# EOS-S3 register map
File version: 0.1
CPU: CM4 r0p1, selectable endian, MPU, FPU, 3 interrupt priority bits
Registers are 32-bit, read-write, reset 0x0 unless marked. A register's access mark holds for its fields unless they carry their own. Offsets are from the block's base; [hi:lo] are bit positions; {n}, {i} and the like mark numbered series; 'fields as' and 'values as' point back to an identical list.

## UART — Universal Asynchronous Receiver Transmitter
Base 0x40010000
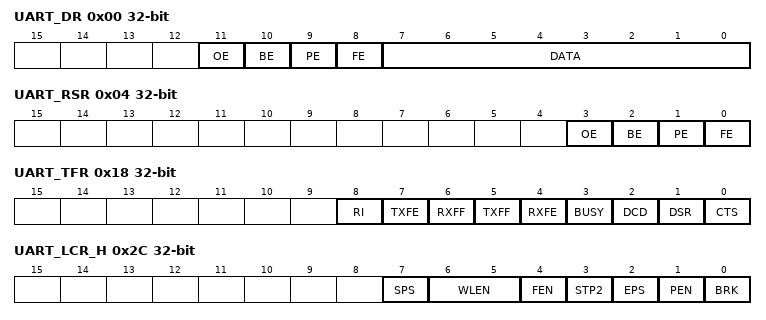
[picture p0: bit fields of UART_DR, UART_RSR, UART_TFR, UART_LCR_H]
0x00 UART_DR — Uart Data register
  [11] OE — Overrun error. This bit is set to 1 if data is received and the receive FIFO is already full. This is cleared to 0 once there is an empty space in the FIFO and a new character can be written to it.
  [10] BE — Break error. This bit is set to 1 if a break condition was detected, indicating that the received data input was held LOW for longer than a full-word transmission time (defined as start, data, parity and stop bits). In FIFO mode, this error is associated with the character at the top of the FIFO. When a break occurs, only one 0 character is loaded into the FIFO. The next character is only enabled after the receive data input goes to a 1 (marking state), and the next valid start bit is received.
  [9] PE — Parity error. When set to 1, it indicates that the parity of the received data character does not match the parity that the EPS and SPS bits in the Line Control Register, UARTLCR_H on page 3-12 select. In FIFO mode, this error is associated with the character at the top of the FIFO.
  [8] FE — Framing error. When set to 1, it indicates that the received character did not have a valid stop bit (a valid stop bit is 1). In FIFO mode, this error is associated with the character at the top of the FIFO.
  [7:0] DATA — Receive (read) data character. Transmit (write) data character.
0x00 UART_IBRD — The integer baud rate divisor.
  [15:0] UART_IBRD
0x00 UART_FBRD — The fractional baud rate divisor.
  [5:0] UART_FBRD
0x04 UART_RSR — UART receive status register/error clear register. (WC)
  [3] OE — Overrun error. This bit is set to 1 if data is received and the FIFO is already full. This bit is cleared to 0 by a write to UARTECR. The FIFO contents remain valid because no more data is written when the FIFO is full, only the contents of the shift register are overwritten. The CPU must now read the data, to empty the FIFO.
  [2] BE — Break error. This bit is set to 1 if a break condition was detected, indicating that the received data input was held LOW for longer than a full-word transmission time (defined as start, data, parity, and stop bits). This bit is cleared to 0 after a write to UARTECR. In FIFO mode, this error is associated with the character at the top of the FIFO. When a break occurs, only one 0 character is loaded into the FIFO. The next character is only enabled after the receive data input goes to a 1 (marking state) and the next valid start bit is received.
  [1] PE — Parity error. When set to 1, it indicates that the parity of the received data character does not match the parity that the EPS and SPS bits in the Line Control Register, UARTLCR_H on page 3-12 select. This bit is cleared to 0 by a write to UARTECR. In FIFO mode, this error is associated with the character at the top of the FIFO.
  [0] FE — Framing error. When set to 1, it indicates that the received character did not have a valid stop bit (a valid stop bit is 1). This bit is cleared to 0 by a write to UARTECR. In FIFO mode, this error is associated with the character at the top of the FIFO
0x18 UART_TFR — UART Flag Register
  [8] RI ro — Ring indicator. This bit is the complement of the UART ring indicator, nUARTRI, modem status input. That is, the bit is 1 when nUARTRI is LOW.
  [7] TXFE ro — Transmit FIFO empty. The meaning of this bit depends on the state of the FEN bit in the Line Control Register, UARTLCR_H on page 3-12. If the FIFO is disabled, this bit is set when the transmit holding register is empty. If the FIFO is enabled, the TXFE bit is set when the transmit FIFO is empty. This bit does not indicate if there is data in the transmit shift register.
  [6] RXFF ro — Receive FIFO full. The meaning of this bit depends on the state of the FEN bit in the UARTLCR_H Register. If the FIFO is disabled, this bit is set when the receive holding register is full. If the FIFO is enabled, the RXFF bit is set when the receive FIFO is full.
  [5] TXFF ro — Transmit FIFO full. The meaning of this bit depends on the state of the FEN bit in the UARTLCR_H Register. If the FIFO is disabled, this bit is set when the transmit holding register is full. If the FIFO is enabled, the TXFF bit is set when the transmit FIFO is full.
  [4] RXFE ro — Receive FIFO empty. The meaning of this bit depends on the state of the FEN bit in the UARTLCR_H Register. If the FIFO is disabled, this bit is set when the receive holding register is empty. If the FIFO is enabled, the RXFE bit is set when the receive FIFO is empty.
  [3] BUSY ro — UART busy. If this bit is set to 1, the UART is busy transmitting data. This bit remains set until the complete byte, including all the stop bits, has been sent from the shift register. This bit is set as soon as the transmit FIFO becomes non-empty, regardless of whether the UART is enabled or not.
  [2] DCD ro — Data carrier detect. This bit is the complement of the UART data carrier detect, nUARTDCD, modem status input. That is, the bit is 1 when nUARTDCD is LOW.
  [1] DSR ro — Data set ready. This bit is the complement of the UART data set ready, nUARTDSR, modem status input. That is, the bit is 1 when nUARTDSR is LOW.
  [0] CTS ro — Clear to send. This bit is the complement of the UART clear to send, nUARTCTS, modem status input. That is, the bit is 1 when nUARTCTS is LOW.
0x20 UART_ILPR — 8-bit low-power divisor value.
  [7:0] UART_ILPR
0x2C UART_LCR_H — UART Line Control Register. This register accesses bit 29 to 22 of the UART Line Control Register, UARTLCR.
  [7] SPS — Stick parity select. This bit has no effect when the PEN bit disables parity checking and generation. See Table 3-11 on page 3-14 for the parity truth table.
    0=disable_stick_parity (Stick parity is disabled); 1=enable_stick_parity (If EPS = 1 => parity bit is trasmitted and checked as a 1, If EPS = 0 => parity bit is trasmitted an checked as a 0)
  [6:5] WLEN — Word length. These bits indicate the number of data bits transmitted or received in a frame
    {v}=use_{v+5}_bit_word (Word lenght of data bits is will be configured as {v+5} bit) (v=0..3)
  [4] FEN — Enable FIFOs:
    0=disable_fifos (FIFOs are disabled (character mode) that is, the FIFOs become 1-byte-deep holding registers); 1=enable_fifos (transmit and receive FIFO buffers are enabled (FIFO mode).)
  [3] STP2 — Two stop bits select. If this bit is set to 1, two stop bits are transmitted at the end of the frame. The receive logic does not check for two stop bits being received.
  [2] EPS — Even parity select. Controls the type of parity the UART uses during transmission and reception. This bit has no effect when the PEN bit disables parity checking and generation. See Table 3-11 on page 3-14 for the parity truth table.
    0=odd_parity (Select odd parity. The UART generates or checks for an odd number of 1s in the data and parity bits.); 1=even_parity (Select even parity. The UART generates or checks for an even number of 1s in the data and parity bits.)
  [1] PEN — Parity enable. See Table 3-11 on page 3-14 for the parity truth table.
    0=parity_disable (parity is disabled and no parity bit added to the data frame); 1=parity_enable (parity checking and generation is enabled.)
  [0] BRK — Send break. If this bit is set to 1, a low-level is continually output on the UARTTXD output, after completing transmission of the current character. For the proper execution of the break command, the software must set this bit for at least two complete frames. For normal use, this bit must be cleared to 0.
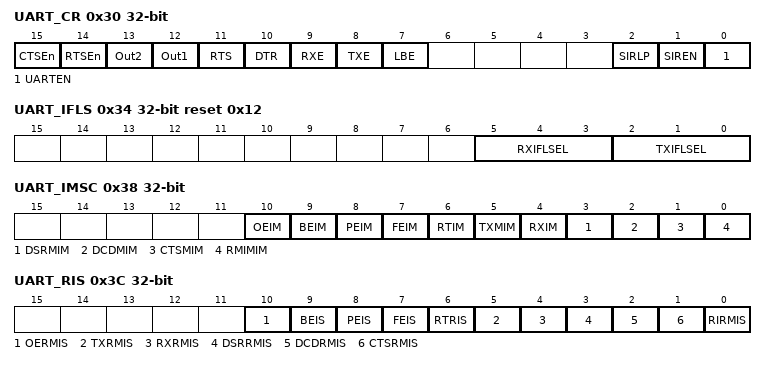
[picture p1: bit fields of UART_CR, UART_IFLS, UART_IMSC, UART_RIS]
0x30 UART_CR — UART Control Register
  [15] CTSEn — CTS hardware flow control enable. If this bit is set to 1, CTS hardware flow control is enabled. Data is only transmitted when the nUARTCTS signal is asserted.
  [14] RTSEn — RTS hardware flow control enable. If this bit is set to 1, RTS hardware flow control is enabled. Data is only requested when there is space in the receive FIFO for it to be received.
  [13] Out2 — This bit is the complement of the UART Out2 (nUARTOut2) modem status output. That is, when the bit is programmed to a 1, the output is 0. For DTE this can be used as Ring Indicator (RI).
  [12] Out1 — This bit is the complement of the UART Out1 (nUARTOut1) modem status output. That is, when the bit is programmed to a 1 the output is 0. For DTE this can be used as Data Carrier Detect (DCD).
  [11] RTS — Request to send. This bit is the complement of the UART request to send, nUARTRTS, modem status output. That is, when the bit is programmed to a 1 then nUARTRTS is LOW.
  [10] DTR — Receive enable. If this bit is set to 1, the receive section of the UART is enabled. Data reception occurs for either UART signals or SIR signals depending on the setting of the SIREN bit. When the UART is disabled in the middle of reception, it completes the current character before stopping.
  [9] RXE — Receive enable. If this bit is set to 1, the receive section of the UART is enabled. Data reception occurs for either UART signals or SIR signals depending on the setting of the SIREN bit. When the UART is disabled in the middle of reception, it completes the current character before stopping.
  [8] TXE — Transmit enable. If this bit is set to 1, the transmit section of the UART is enabled. Data transmission occurs for either UART signals, or SIR signals depending on the setting of the SIREN bit. When the UART is disabled in the middle of transmission, it completes the current character before stopping.
  [7] LBE — Loopback enable. If this bit is set to 1 and the SIREN bit is set to 1 and the SIRTEST bit in the Test Control Register, UARTTCR on page 4-5 is set to 1, then the nSIROUT path is inverted, and fed through to the SIRIN path. The SIRTEST bit in the Test register must be set to 1 to override the normal half-duplex SIR operation. This must be the requirement for accessing the Test registers during normal operation, and SIRTEST must be cleared to 0 when loopback testing is finished. This feature reduces the amount of external coupling required during system Test. If this bit is set to 1, and the SIRTEST bit is set to 0, the UARTTXD path is fed through to the UARTRXD path. In either SIR mode or UART mode, when this bit is set, the modem outputs are also fed through to the modem inputs. This bit is cleared to 0 on reset, to disable loopback.
  [2] SIRLP — SIR low-power IrDA mode. This bit selects the IrDA encoding mode. If this bit is cleared to 0, low-level bits are transmitted as an active high pulse with a width of 3/16th of the bit period. If this bit is set to 1, low-level bits are transmitted with a pulse width that is 3 times the period of the IrLPBaud16 input signal, regardless of the selected bit rate. Setting this bit uses less power, but might reduce transmission distances.
  [1] SIREN — Siren enable. This bit has no effect if the UARTEN bit disables the UART.
    0=siren_disable (IrDA SIR ENDEC is disabled. nSIROUT remains LOW (no light pulse generated), and signal transitions on SIRIN have no effect.); 1=siren_enable (IrDA SIR ENDEC is enabled. Data is transmitted and received on nSIROUT and SIRIN. UARTTXD remains HIGH, in the marking state. Signal transitions on UARTRXD or modem status inputs have no effect.)
  [0] UARTEN — UART enable
    0=uart_disable (UART is disabled. If the UART is disabled in the middle of transmission or reception, it completes the current character before stopping.); 1=uart_enable (the UART is enabled. Data transmission and reception occurs for either UART signals or SIR signals depending on the setting of the SIREN bit.)
0x34 UART_IFLS reset 0x12 — Interrupt FIFO Level Select Register
  [5:3] RXIFLSEL — Receive interrupt FIFO level select. The trigger points for the receive interrupt are as follows
    0=one_eight (Trigger when corresponding FIFO becomes ≤ 1/8 full); 1=one_quarter (Trigger when corresponding FIFO becomes ≤ 1/4 full); 2=one_half (Trigger when corresponding FIFO becomes ≤ 1/2 full); 3=three_quarters (Trigger when corresponding FIFO becomes ≤ 3/4 full); 4=seven_eights (Trigger when corresponding FIFO becomes ≤ 7/8 full)
  [2:0] TXIFLSEL — Transmit interrupt FIFO level select. The trigger points for the receive interrupt are as follows
    values as RXIFLSEL
0x38 UART_IMSC — Interrupt Mask Set/Clear Register
  [10] OEIM — Overrun error interrupt mask.
  [9] BEIM — Break error interrupt mask.
  [8] PEIM — Parity error interrupt mask.
  [7] FEIM — Framing error interrupt mask.
  [6] RTIM — Receive timeout interrupt mask.
  [5] TXMIM — Transmit interrupt mask.
  [4] RXIM — Receive interrupt mask.
  [3] DSRMIM — nUARTDSR interrupt mask.
  [2] DCDMIM — nUARTDCD modem interrupt mask.
  [1] CTSMIM — nUARTCTS modem interrupt mask.
  [0] RMIMIM — nUARTRI modem interrupt mask.
0x3C UART_RIS — Raw interrupt status register
  [10] OERMIS ro — Overrun error interrupt status (raw interrupt state)
  [9] BEIS ro — Break error interrupt status (raw interrupt state)
  [8] PEIS ro — Parity error interrupt status (raw interrupt state)
  [7] FEIS ro — Framing error interrupt status (raw interrupt state)
  [6] RTRIS ro — Receive timeout interrupt status (raw interrupt state)
  [5] TXRMIS ro — Transmit interrupt status (raw interrupt state)
  [4] RXRMIS ro — Receive interrupt status (raw interrupt state)
  [3] DSRRMIS ro — nUARTDSR interrupt status (raw interrupt state)
  [2] DCDRMIS ro — nUARTDCD interrupt status (raw interrupt state)
  [1] CTSRMIS ro — nUARTCTS interrupt status (raw interrupt state)
  [0] RIRMIS ro — nUARTRI interrupt status (raw interrupt state)
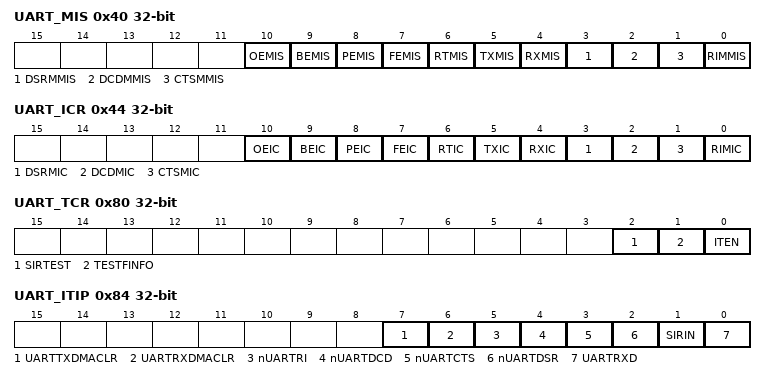
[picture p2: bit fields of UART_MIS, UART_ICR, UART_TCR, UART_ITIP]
0x40 UART_MIS — Masked interrupt status register
  [10] OEMIS ro — Overrun error masked interrupt status (masked interrupt state)
  [9] BEMIS ro — Break error masked interrupt status (masked interrupt state)
  [8] PEMIS ro — Parity error masked interrupt status (masked interrupt state)
  [7] FEMIS ro — Framing error masked interrupt status (masked interrupt state)
  [6] RTMIS ro — Receive timeout masked interrupt status (masked interrupt state)
  [5] TXMIS ro — Transmit masked interrupt status (masked interrupt state)
  [4] RXMIS ro — Receive masked interrupt status (masked interrupt state)
  [3] DSRMMIS ro — nUARTDSR modem masked interrupt status (masked interrupt state)
  [2] DCDMMIS ro — nUARTDCD modem masked interrupt status (masked interrupt state)
  [1] CTSMMIS ro — nUARTCTS modem masked interrupt status (masked interrupt state)
  [0] RIMMIS ro — nUARTRI modem masked interrupt status (masked interrupt state)
0x44 UART_ICR — Interrupt clear register
  [10] OEIC wo — Overrun error interrupt clear. Writing a 1 clears the interrupt.
  [9] BEIC wo — Break error interrupt clear. Writing a 1 clears the interrupt.
  [8] PEIC wo — Parity error interrupt clear. Writing a 1 clears the interrupt.
  [7] FEIC wo — Framing error interrupt clear. Writing a 1 clears the interrupt.
  [6] RTIC wo — Receive timeout interrupt clear. Writing a 1 clears the interrupt.
  [5] TXIC wo — Transmit interrupt clear. Writing a 1 clears the interrupt.
  [4] RXIC wo — Receive interrupt clear. Writing a 1 clears the interrupt.
  [3] DSRMIC wo — nUARTDSR modem interrupt clear. Writing a 1 clears the interrupt.
  [2] DCDMIC wo — nUARTDCD modem interrupt clear. Writing a 1 clears the interrupt.
  [1] CTSMIC wo — nUARTCTS modem interrupt clear. Writing a 1 clears the interrupt.
  [0] RIMIC wo — nUARTRI modem interrupt clear. Writing a 1 clears the interrupt.
0x80 UART_TCR — Test Control Register
  [2] SIRTEST wo — Siren Test enable.
  [1] TESTFINFO wo — Test FIFO enable.
  [0] ITEN wo — Integration Test enable.
0x84 UART_ITIP — Integration Test input register
  [7] UARTTXDMACLR, [6] UARTRXDMACLR, [5] nUARTRI ro, [4] nUARTDCD ro, [3] nUARTCTS ro, [2] nUARTDSR ro, [1] SIRIN ro, [0] UARTRXD ro
0x88 UART_ITOP — Integration Test output register
  [15:0] UART_ITOP — Integration Test output.
0x8C UART_TDR — Test data register
  [10:0] UART_TDR — Test data
0xFE0 UART_PeriphID0 (reset mask 0x11) — UART Peripheral ID 0 register
  [7:0] UART_PeriphID0 ro
0xFE4 UART_PeriphID1 reset 0x10 — UART Peripheral ID 1 register
  [7:0] UART_PeriphID1 ro
0xFE8 UART_PeriphID2 reset 0x34 — UART Peripheral ID 2 register
  [7:0] UART_PeriphID2 ro
0xFEC UART_PeriphID3 — UART Peripheral ID 3 register
  [7:0] UART_PeriphID3 ro
0xFF0 UART_PCellID0 reset 0xD
  [7:0] UART_PCellID0 ro
0xFF4 UART_PCellID1 reset 0xF0
  [7:0] UART_PCellID1 ro
0xFF8 UART_PCellID2 reset 0x5
  [7:0] UART_PCellID2 ro
0xFFC UART_PCellID4 reset 0xB1
  [7:0] UART_PCellID4 ro
